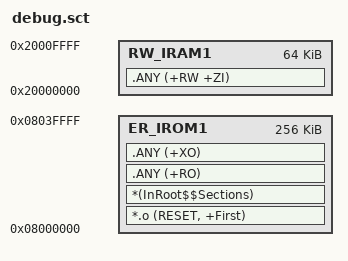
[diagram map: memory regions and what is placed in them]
; *************************************************************
; *** Scatter-Loading Description File generated by uVision ***
; *************************************************************
;LR_IROM2 0x080CD000 0x00000800  {    ; load region size_region
;  ER_IROM2 0x080CD000 0x00000800  {  ; load address = execution address
 ; .ANY (pg_encry_data)
;  }
;}
LR_IROM1 0x08000000 0x00040000  {    ; load region size_region
  ER_IROM1 0x08000000 0x00040000  {  ; load address = execution address
   *.o (RESET, +First)
   *(InRoot$$Sections)
   .ANY (+RO)
   .ANY (+XO)
  }
  RW_IRAM1 0x20000000 0x00010000  {  ; RW data
   .ANY (+RW +ZI)
  }
}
